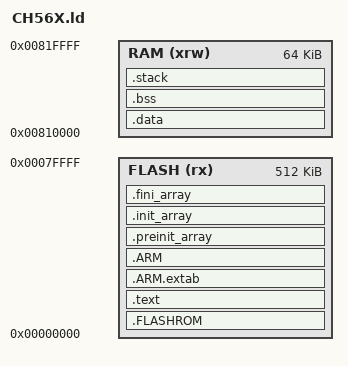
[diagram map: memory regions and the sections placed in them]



/* Entry Point */
ENTRY(_start)

/* Highest address of the user mode stack */

/* Generate a link error if heap and stack don't fit into RAM */

__stack_size = 0x400;
/* Specify the memory areas */
MEMORY
{
  FLASH (rx)      : ORIGIN = 0x00000000, LENGTH = 512K
  RAM (xrw)       : ORIGIN = 0x00810000, LENGTH = 64K
}

/* Define output sections */
SECTIONS
{
  /* The startup code goes first into FLASH */
  .FLASHROM :
  {
    . = ALIGN(4);
   KEEP(*(.init))
   *.SYSFREQ.o(*)
   *(.text)           /* .text sections (code) */
    *(.text*)          /* .text* sections (code) */
    *(.rodata)         /* .rodata sections (constants, strings, etc.) */
    *(.rodata*)        /* .rodata* sections (constants, strings, etc.) */
    *(.glue_7)         /* glue arm to thumb code */
    *(.glue_7t)        /* glue thumb to arm code */
	*(.eh_frame)
   . = ALIGN(4);
  } >FLASH

  /* The program code and other data goes into FLASH */

  .text :
  {
    . = ALIGN(4);
    *(.text)           /* .text sections (code) */
    *(.text*)          /* .text* sections (code) */
    *(.rodata)         /* .rodata sections (constants, strings, etc.) */
    *(.rodata*)        /* .rodata* sections (constants, strings, etc.) */
    *(.glue_7)         /* glue arm to thumb code */
    *(.glue_7t)        /* glue thumb to arm code */
	*(.eh_frame)
    . = ALIGN(4);
    _etext = .;        /* define a global symbols at end of code */
  } >FLASH


   .ARM.extab   : { *(.ARM.extab* .gnu.linkonce.armextab.*) } >FLASH
    .ARM : {
    __exidx_start = .;
      *(.ARM.exidx*)
      __exidx_end = .;
    } >FLASH

  .preinit_array     :
  {
    PROVIDE_HIDDEN (__preinit_array_start = .);
    KEEP (*(.preinit_array*))
    PROVIDE_HIDDEN (__preinit_array_end = .);
  } >FLASH
  .init_array :
  {
    PROVIDE_HIDDEN (__init_array_start = .);
    KEEP (*(SORT(.init_array.*)))
    KEEP (*(.init_array*))
    PROVIDE_HIDDEN (__init_array_end = .);
  } >FLASH
  .fini_array :
  {
    PROVIDE_HIDDEN (__fini_array_start = .);
    KEEP (*(.fini_array*))
    KEEP (*(SORT(.fini_array.*)))
    PROVIDE_HIDDEN (__fini_array_end = .);
  } >FLASH

  /* used by the startup to initialize data */
  _sidata = .;

  /* Initialized data sections goes into RAM, load LMA copy after code */
  .data : AT ( _sidata )
  {
    . = ALIGN(4);
    _sdata = .;        /* create a global symbol at data start */
    *(.data)           /* .data sections */
    *(.data*)          /* .data* sections */

    . = ALIGN(4);
    _edata = .;        /* define a global symbol at data end */
  } >RAM

  /* Uninitialized data section */
  . = ALIGN(4);
  .bss :
  {
    /* This is used by the startup in order to initialize the .bss secion */
    _sbss = .;         /* define a global symbol at bss start */
    __bss_start__ = _sbss;
    *(.bss)
    *(.bss*)
    *(COMMON)

    . = ALIGN(4);
    _ebss = .;         /* define a global symbol at bss end */
    __bss_end__ = _ebss;
  } >RAM

  PROVIDE ( end = _ebss );
  PROVIDE ( _end = _ebss );
.stack ORIGIN(RAM) + LENGTH(RAM) - __stack_size :
    {
        . = ALIGN(4);
        PROVIDE(_susrstack = . );
        . = . + __stack_size;
        PROVIDE( _eusrstack = .);
    } >RAM 

}
